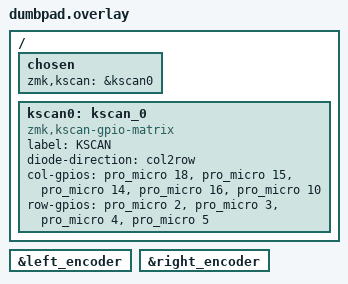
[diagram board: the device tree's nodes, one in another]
/*
 * Copyright (c) 2020 Ryan Cross
 *
 * SPDX-License-Identifier: MIT
 */

#include "dumbpad.dtsi"

/ {
    chosen {
        zmk,kscan = &kscan0;
    };

    kscan0: kscan_0 {
        compatible = "zmk,kscan-gpio-matrix";
        label = "KSCAN";
        diode-direction = "col2row";

        col-gpios
		= <&pro_micro 18 GPIO_ACTIVE_HIGH>
        	, <&pro_micro 15 GPIO_ACTIVE_HIGH>
		, <&pro_micro 14 GPIO_ACTIVE_HIGH>
		, <&pro_micro 16 GPIO_ACTIVE_HIGH>
		, <&pro_micro 10 GPIO_ACTIVE_HIGH>
		;

        row-gpios
        = <&pro_micro 2 (GPIO_ACTIVE_HIGH | GPIO_PULL_DOWN)>
        , <&pro_micro 3 (GPIO_ACTIVE_HIGH | GPIO_PULL_DOWN)>
        , <&pro_micro 4 (GPIO_ACTIVE_HIGH | GPIO_PULL_DOWN)>
        , <&pro_micro 5 (GPIO_ACTIVE_HIGH | GPIO_PULL_DOWN)>
        ;
    };
};

&left_encoder {
    status = "okay";
};
&right_encoder {
    status = "okay";
};
